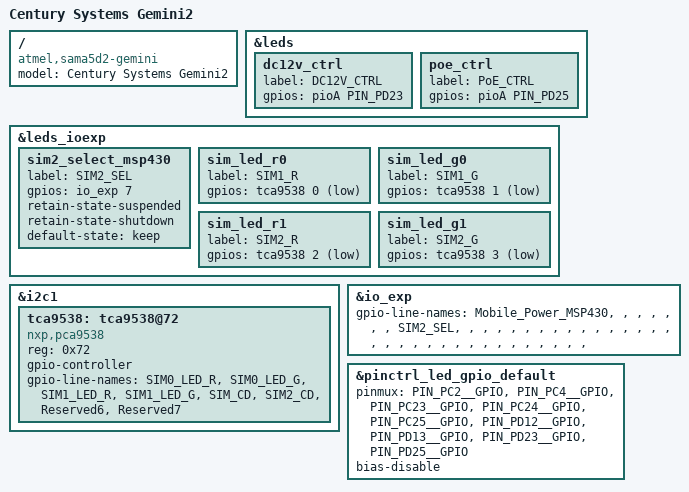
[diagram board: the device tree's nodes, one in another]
// SPDX-License-Identifier: (GPL-2.0+ OR MIT)
/*
 * at91-centurysys-gemini2-02.dts - Device Tree file for Century Systems Gemini2 board
 *
 * Copyright (C) 2023-2026 Century Systems
 */
/dts-v1/;
#include "at91-centurysys-gemini-common.dtsi"

/ {
	model = "Century Systems Gemini2";
	compatible = "atmel,sama5d2-gemini", "atmel,sama5d2", "atmel,sama5";
};

&leds {
	dc12v_ctrl {
		label = "DC12V_CTRL";
		gpios = <&pioA PIN_PD23 GPIO_ACTIVE_HIGH>;
	};

	poe_ctrl {
		label = "PoE_CTRL";
		gpios = <&pioA PIN_PD25 GPIO_ACTIVE_HIGH>;
	};
};

&leds_ioexp {
	sim2_select_msp430 {
		label = "SIM2_SEL";
		gpios = <&io_exp 7 GPIO_ACTIVE_HIGH>;
		retain-state-suspended;
		retain-state-shutdown;
		default-state = "keep";
	};

	sim_led_r0 {
		label = "SIM1_R";
		gpios = <&tca9538 0 GPIO_ACTIVE_LOW>;
	};

	sim_led_g0 {
		label = "SIM1_G";
		gpios = <&tca9538 1 GPIO_ACTIVE_LOW>;
	};

	sim_led_r1 {
		label = "SIM2_R";
		gpios = <&tca9538 2 GPIO_ACTIVE_LOW>;
	};

	sim_led_g1 {
		label = "SIM2_G";
		gpios = <&tca9538 3 GPIO_ACTIVE_LOW>;
	};
};

&i2c1 {
	/* SIM selection/status GPIO expander. */
	tca9538: tca9538@72 {
		compatible = "nxp,pca9538";
		reg = <0x72>;
		gpio-controller;
		#gpio-cells = <2>;
		gpio-line-names = "SIM0_LED_R",
				  "SIM0_LED_G",
				  "SIM1_LED_R",
				  "SIM1_LED_G",
				  "SIM_CD",
				  "SIM2_CD",
				  "Reserved6",
				  "Reserved7";
	};
};

&io_exp {
	gpio-line-names = "Mobile_Power_MSP430", "", "", "", "", "", "", "SIM2_SEL",
			  "", "", "", "", "", "", "", "", /* Reserved */
			  "", "", "", "", "", "", "", "", /* Reserved */
			  "", "", "", "", "", "", "", "", /* Reserved */
			  "", "", "", "", "", "", "", ""; /* Reserved */
};

&pinctrl_led_gpio_default {
	pinmux = <PIN_PC2__GPIO>,
		 <PIN_PC4__GPIO>,
		 <PIN_PC23__GPIO>,
		 <PIN_PC24__GPIO>,
		 <PIN_PC25__GPIO>,
		 <PIN_PD12__GPIO>,
		 <PIN_PD13__GPIO>,
		 <PIN_PD23__GPIO>,
		 <PIN_PD25__GPIO>;
	bias-disable;
};
